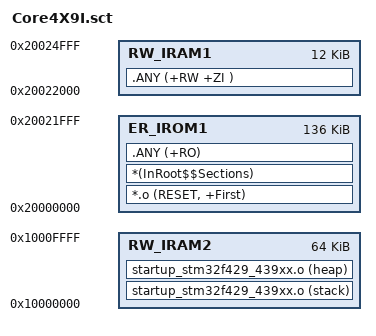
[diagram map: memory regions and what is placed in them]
; *************************************************************
; *** Scatter-Loading Description File generated by uVision ***
; *************************************************************

LR_IROM1 0x20000000 0x00022000  {    ; load region size_region
  ER_IROM1 0x20000000 0x00022000  {  ; load address = execution address
   *.o (RESET, +First)
   *(InRoot$$Sections)
   .ANY (+RO)
  }
  RW_IRAM1 0x20022000 0x00003000  {  ; RW data
   .ANY (+RW +ZI )
  }
  RW_IRAM2 0x10000000 0x00010000  {
   startup_stm32f429_439xx.o (stack)
   startup_stm32f429_439xx.o (heap)
	
  }
	;ER_IROM2 0x900C0000 0x00020000  {    ; load region size_region
	 ; screen.o (+RO)
	;  	  
  ;}
}



